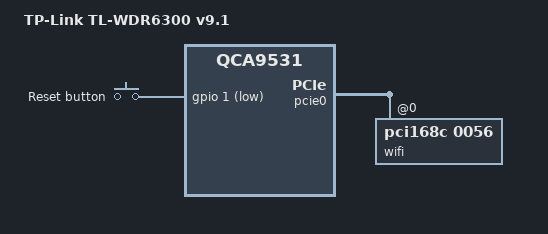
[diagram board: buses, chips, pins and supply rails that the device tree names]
// SPDX-License-Identifier: GPL-2.0-or-later OR MIT

#include "qca9531_tplink_tl-wdr6300xx.dtsi"

/ {
	compatible = "tplink,tl-wdr6300-v9.1", "tplink,tl-wdr6300-v6", "qca,qca9531";
	model = "TP-Link TL-WDR6300 v9.1";

	aliases {
		serial0 = &uart;
		// led-boot = &led_wan;
		// led-failsafe = &led_wan;
		// led-upgrade = &led_wan;
	};

	keys {
		compatible = "gpio-keys";

		pinctrl-names = "default";
		pinctrl-0 = <&jtag_disable_pins>;

		reset {
			label = "Reset button";
			linux,code = <KEY_RESTART>;
			gpios = <&gpio 1 GPIO_ACTIVE_LOW>;
			debounce-interval = <60>;
		};
	};
};

&pcie0 {
	status = "okay";

	wifi@0,0 {
		compatible = "pci168c,0056";
		reg = <0x0000 0 0 0 0>;
	};
};
